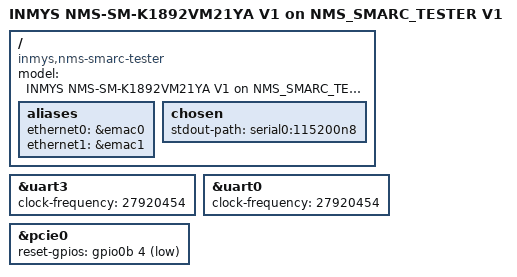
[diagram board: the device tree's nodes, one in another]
// SPDX-License-Identifier: GPL-2.0+
/*
 * INMYS NMS-SM-K1892VM21YA V1 on NMS_SMARC_TESTER V1 - U-Boot device tree
 *
 * Copyright (C) 2026 INMYS
 */

/dts-v1/;

#include <dt-bindings/gpio/gpio.h>

#include "mcom03r-nms-sm-k1892vm21ya.dtsi"

/ {
	model = "INMYS NMS-SM-K1892VM21YA V1 on NMS_SMARC_TESTER V1";
	compatible = "inmys,nms-smarc-tester",
		     "inmys,nms-sm-k1892vm21ya",
		     "inmys,nms-sm-k1892",
		     "elvees,mcom03r";

	aliases {
		ethernet0 = &emac0;
		ethernet1 = &emac1;
	};

	chosen {
		stdout-path = "serial0:115200n8";
	};
};

&uart3 {
	status = "okay";
	clock-frequency = <27920454>;
};

&uart0 {
	status = "okay";
	clock-frequency = <27920454>;
};

&pcie0 {
	status = "okay";
	reset-gpios = <&gpio0b 4 GPIO_ACTIVE_LOW>;
};
